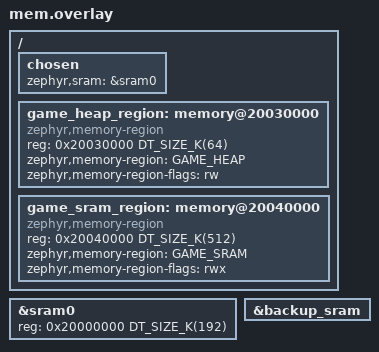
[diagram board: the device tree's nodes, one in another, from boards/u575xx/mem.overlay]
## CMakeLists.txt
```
# SPDX-License-Identifier: Apache-2.0
#
# -----------------------------------------------------------------------------
# Generated with AI assistance by Claude (Anthropic Opus 4.8, model
# claude-opus-4-8) on 2026-06-07. Reviewed and maintained by the project author.
# -----------------------------------------------------------------------------
#
# zboy console firmware — Zephyr application
#
# Directory layout:
#   src/             application code that Zephyr builds
#   include/         headers for everything in src/
#   lib/src          game-side support library sources
#   lib/include      public headers for lib/ (also used by the linker scripts)
#   boards/          devicetree overlays + custom board definitions
#     u575xx/        shared SoC overlay (memory map) — applied for every variant
#     nucleo_u575zi/ overlays for the NUCLEO-U575ZI-Q prototype board
#     u575vi/        custom production board definition (selected with -b u575vi)
#   linker/          linker-script fragments
#     u575xxx/       game memory regions (SRAM2/SRAM3) — applied for every variant
#
# Variant selection (board + overlays) is driven by scripts/build.sh, which sets
# BOARD, BOARD_ROOT and EXTRA_DTC_OVERLAY_FILE on the command line.

cmake_minimum_required(VERSION 3.20.0)

find_package(Zephyr REQUIRED HINTS $ENV{ZEPHYR_BASE})
project(zboy LANGUAGES C ASM)

# --- Include paths -----------------------------------------------------------
# include/ holds headers for src/; lib/include holds the public library headers.
# Absolute paths are required here: relative entries are dropped from the include
# list used to preprocess the linker scripts. (The linker fragment also includes
# mem_defs.h via a path relative to itself, so it does not depend on this.)
zephyr_include_directories(${CMAKE_CURRENT_SOURCE_DIR}/include)
zephyr_include_directories(${CMAKE_CURRENT_SOURCE_DIR}/lib/include)

# --- Application + library sources --------------------------------------------
file(GLOB app_sources CONFIGURE_DEPENDS ${CMAKE_CURRENT_SOURCE_DIR}/src/*.c)
file(GLOB lib_sources CONFIGURE_DEPENDS ${CMAKE_CURRENT_SOURCE_DIR}/lib/src/*.c)
target_sources(app PRIVATE ${app_sources} ${lib_sources})

# --- Custom linker sections ---------------------------------------------------
# Injects the GAME_SRAM / GAME_HEAP section layout. The regions themselves are
# created by the memory-region nodes in boards/u575xx/mem.overlay.
zephyr_linker_sources(SECTIONS linker/u575xxx/game_mem.ld)
```

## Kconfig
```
# -----------------------------------------------------------------------------
# Generated with AI assistance by Claude (Anthropic Opus 4.8, model
# claude-opus-4-8) on 2026-06-07. Reviewed and maintained by the project author.
# -----------------------------------------------------------------------------
#
# zboy console firmware — application Kconfig root.
#
# When an application provides its own Kconfig, it becomes the Kconfig tree root
# and is responsible for sourcing Zephyr's configuration. Project-specific
# options are declared here (and in sub-Kconfigs) before that source line.

menu "zboy console options"

rsource "lib/Kconfig"

endmenu

source "Kconfig.zephyr"
```

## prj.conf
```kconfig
# -----------------------------------------------------------------------------
# Generated with AI assistance by Claude (Anthropic Opus 4.8, model
# claude-opus-4-8) on 2026-06-07. Reviewed and maintained by the project author.
# -----------------------------------------------------------------------------
#
# zboy console firmware — base application configuration.
#
# Variant-independent defaults live here. Board-specific tuning belongs in the
# board files (boards/<board>/<board>_defconfig) or in variant overlays.

# Console working stack for the Zephyr main thread.
CONFIG_MAIN_STACK_SIZE=4096
```

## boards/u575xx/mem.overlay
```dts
/*
 * boards/u575xx/mem.overlay
 *
 * Memory layout for u575xxx chips
 *
 * Physical map (from RM0456 Figure 4 + Table 6):
 *   SRAM1  0x20000000  192KB  -> Zephyr kernel, stacks, console buffers, API table
 *   SRAM2  0x20030000   64KB  -> Game heap (API-managed, MPU RW for game code)
 *   SRAM3  0x20040000  512KB  -> Game code, game stack, framebuffers, palette
 *   SRAM4  0x28000000   16KB  -> D3 domain, reserved for future low-power use
 *   BKPSRAM 0x40036400   2KB  -> Crash log, save-dirty flag, sleep/resume state
 */

/ {
  chosen {
    zephyr,sram = &sram0;
  };

  game_heap_region: memory@20030000 {
    compatible = "zephyr,memory-region", "mmio-sram";
    reg = <0x20030000 DT_SIZE_K(64)>;
    zephyr,memory-region = "GAME_HEAP";
    zephyr,memory-region-flags = "rw";
  };

  game_sram_region: memory@20040000 {
    compatible = "zephyr,memory-region", "mmio-sram";
    reg = <0x20040000 DT_SIZE_K(512)>;
    zephyr,memory-region = "GAME_SRAM";
    zephyr,memory-region-flags = "rwx";
  };
};

/* restrict SRAM1 to only 192kb 
* zephyr defined sram0 as SRAM1+2+3 
* but zephyr's sram should be restricted to SRAM1
*/
&sram0 {
  reg = <0x20000000 DT_SIZE_K(192)>;
};

&backup_sram {
  status = "okay";
};
```

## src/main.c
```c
/*
 * zboy console firmware — entry point.
 *
 * Placeholder main for bring-up. Including mem_defs.h here compiles the memory
 * budget _Static_assert checks in a C context (the same header is also consumed
 * by the linker script, where those asserts are skipped).
 */

#include <zephyr/kernel.h>

#include <mem_defs.h>

int main(void)
{
	return 0;
}
```
